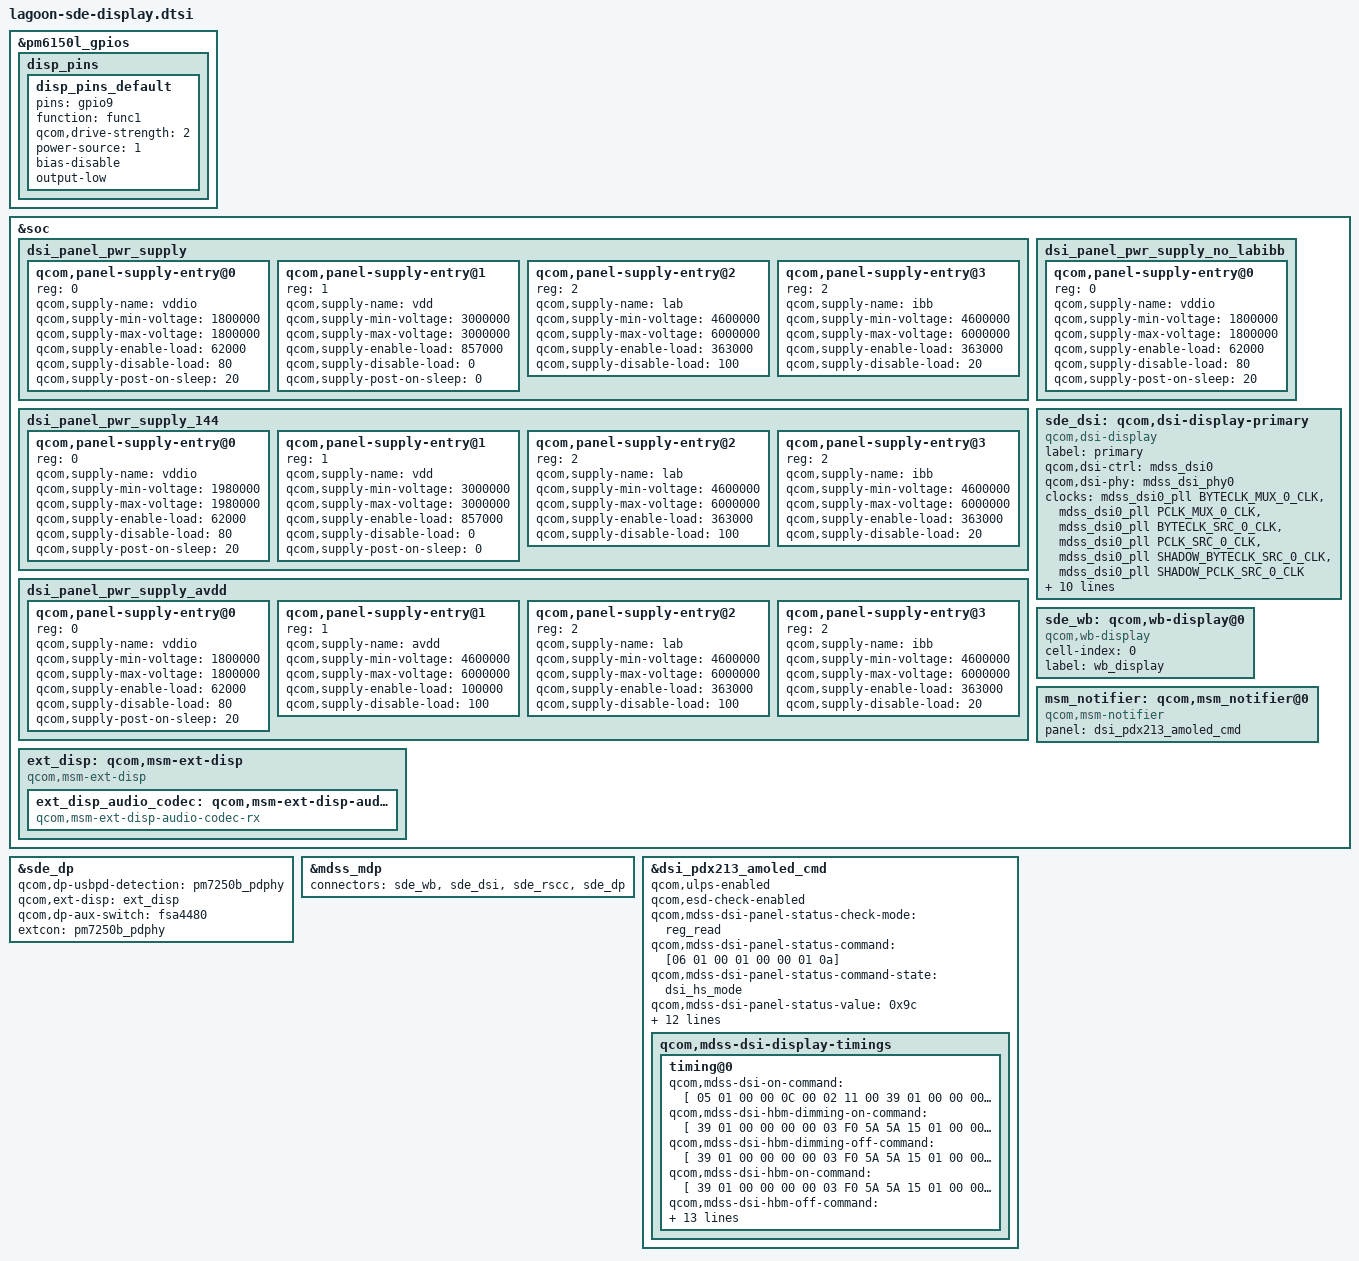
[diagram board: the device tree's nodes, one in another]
#include "dsi-panel-pdx213-amoled-fhd-cmd.dtsi"
#include <dt-bindings/clock/mdss-10nm-pll-clk.h>

&pm6150l_gpios {
	disp_pins {
		disp_pins_default: disp_pins_default {
			pins = "gpio9";
			function = "func1";
			qcom,drive-strength = <2>;
			power-source = <1>;
			bias-disable;
			output-low;
		};
	};
};

&soc {
	dsi_panel_pwr_supply: dsi_panel_pwr_supply {
		#address-cells = <1>;
		#size-cells = <0>;

		qcom,panel-supply-entry@0 {
			reg = <0>;
			qcom,supply-name = "vddio";
			qcom,supply-min-voltage = <1800000>;
			qcom,supply-max-voltage = <1800000>;
			qcom,supply-enable-load = <62000>;
			qcom,supply-disable-load = <80>;
			qcom,supply-post-on-sleep = <20>;
		};

		qcom,panel-supply-entry@1 {
			reg = <1>;
			qcom,supply-name = "vdd";
			qcom,supply-min-voltage = <3000000>;
			qcom,supply-max-voltage = <3000000>;
			qcom,supply-enable-load = <857000>;
			qcom,supply-disable-load = <0>;
			qcom,supply-post-on-sleep = <0>;
		};

		qcom,panel-supply-entry@2 {
			reg = <2>;
			qcom,supply-name = "lab";
			qcom,supply-min-voltage = <4600000>;
			qcom,supply-max-voltage = <6000000>;
			qcom,supply-enable-load = <363000>;
			qcom,supply-disable-load = <100>;
		};

		qcom,panel-supply-entry@3 {
			reg = <2>;
			qcom,supply-name = "ibb";
			qcom,supply-min-voltage = <4600000>;
			qcom,supply-max-voltage = <6000000>;
			qcom,supply-enable-load = <363000>;
			qcom,supply-disable-load = <20>;
		};
	};

	dsi_panel_pwr_supply_144: dsi_panel_pwr_supply_144 {
		#address-cells = <1>;
		#size-cells = <0>;

		qcom,panel-supply-entry@0 {
			reg = <0>;
			qcom,supply-name = "vddio";
			qcom,supply-min-voltage = <1980000>;
			qcom,supply-max-voltage = <1980000>;
			qcom,supply-enable-load = <62000>;
			qcom,supply-disable-load = <80>;
			qcom,supply-post-on-sleep = <20>;
		};

		qcom,panel-supply-entry@1 {
			reg = <1>;
			qcom,supply-name = "vdd";
			qcom,supply-min-voltage = <3000000>;
			qcom,supply-max-voltage = <3000000>;
			qcom,supply-enable-load = <857000>;
			qcom,supply-disable-load = <0>;
			qcom,supply-post-on-sleep = <0>;
		};

		qcom,panel-supply-entry@2 {
			reg = <2>;
			qcom,supply-name = "lab";
			qcom,supply-min-voltage = <4600000>;
			qcom,supply-max-voltage = <6000000>;
			qcom,supply-enable-load = <363000>;
			qcom,supply-disable-load = <100>;
		};

		qcom,panel-supply-entry@3 {
			reg = <2>;
			qcom,supply-name = "ibb";
			qcom,supply-min-voltage = <4600000>;
			qcom,supply-max-voltage = <6000000>;
			qcom,supply-enable-load = <363000>;
			qcom,supply-disable-load = <20>;
		};
	};

	dsi_panel_pwr_supply_avdd: dsi_panel_pwr_supply_avdd {
		#address-cells = <1>;
		#size-cells = <0>;

		qcom,panel-supply-entry@0 {
			reg = <0>;
			qcom,supply-name = "vddio";
			qcom,supply-min-voltage = <1800000>;
			qcom,supply-max-voltage = <1800000>;
			qcom,supply-enable-load = <62000>;
			qcom,supply-disable-load = <80>;
			qcom,supply-post-on-sleep = <20>;
		};

		qcom,panel-supply-entry@1 {
			reg = <1>;
			qcom,supply-name = "avdd";
			qcom,supply-min-voltage = <4600000>;
			qcom,supply-max-voltage = <6000000>;
			qcom,supply-enable-load = <100000>;
			qcom,supply-disable-load = <100>;
		};

		qcom,panel-supply-entry@2 {
			reg = <2>;
			qcom,supply-name = "lab";
			qcom,supply-min-voltage = <4600000>;
			qcom,supply-max-voltage = <6000000>;
			qcom,supply-enable-load = <363000>;
			qcom,supply-disable-load = <100>;
		};

		qcom,panel-supply-entry@3 {
			reg = <2>;
			qcom,supply-name = "ibb";
			qcom,supply-min-voltage = <4600000>;
			qcom,supply-max-voltage = <6000000>;
			qcom,supply-enable-load = <363000>;
			qcom,supply-disable-load = <20>;
		};
	};

	dsi_panel_pwr_supply_no_labibb: dsi_panel_pwr_supply_no_labibb {
		#address-cells = <1>;
		#size-cells = <0>;

		qcom,panel-supply-entry@0 {
			reg = <0>;
			qcom,supply-name = "vddio";
			qcom,supply-min-voltage = <1800000>;
			qcom,supply-max-voltage = <1800000>;
			qcom,supply-enable-load = <62000>;
			qcom,supply-disable-load = <80>;
			qcom,supply-post-on-sleep = <20>;
		};
	};

	sde_dsi: qcom,dsi-display-primary {
		compatible = "qcom,dsi-display";
		label = "primary";

		qcom,dsi-ctrl = <&mdss_dsi0>;
		qcom,dsi-phy = <&mdss_dsi_phy0>;

		clocks = <&mdss_dsi0_pll BYTECLK_MUX_0_CLK>,
			 <&mdss_dsi0_pll PCLK_MUX_0_CLK>,
			 <&mdss_dsi0_pll BYTECLK_SRC_0_CLK>,
			 <&mdss_dsi0_pll PCLK_SRC_0_CLK>,
			 <&mdss_dsi0_pll SHADOW_BYTECLK_SRC_0_CLK>,
			 <&mdss_dsi0_pll SHADOW_PCLK_SRC_0_CLK>;
		clock-names = "mux_byte_clk0", "mux_pixel_clk0",
				"src_byte_clk0", "src_pixel_clk0",
				"shadow_byte_clk0", "shadow_pixel_clk0";

		pinctrl-names = "panel_active", "panel_suspend";
		pinctrl-0 = <&sde_te_active &disp_pins_default>;
		pinctrl-1 = <&sde_te_suspend>;

		qcom,platform-te-gpio = <&tlmm 23 0>;
		qcom,panel-te-source = <0>;

		vddio-supply = <&L1E>;
		vdd-supply = <&L6A>;
		lab-supply = <&ab_vreg>;
		ibb-supply = <&ibb_vreg>;

		qcom,mdp = <&mdss_mdp>;
		qcom,dsi-default-panel = <&dsi_pdx213_amoled_cmd>;
	};

	sde_wb: qcom,wb-display@0 {
		compatible = "qcom,wb-display";
		cell-index = <0>;
		label = "wb_display";
	};

	msm_notifier: qcom,msm_notifier@0 {
		compatible = "qcom,msm-notifier";
		panel = <&dsi_pdx213_amoled_cmd>;
	};

	ext_disp: qcom,msm-ext-disp {
		compatible = "qcom,msm-ext-disp";

		ext_disp_audio_codec: qcom,msm-ext-disp-audio-codec-rx {
			compatible = "qcom,msm-ext-disp-audio-codec-rx";
		};
	};

};

&sde_dp {
	qcom,dp-usbpd-detection = <&pm7250b_pdphy>;
	qcom,ext-disp = <&ext_disp>;
	qcom,dp-aux-switch = <&fsa4480>;

	extcon = <&pm7250b_pdphy>;
};

&mdss_mdp {
	connectors = <&sde_wb &sde_dsi &sde_rscc &sde_dp>;
};

&dsi_pdx213_amoled_cmd {
	qcom,ulps-enabled;
	qcom,esd-check-enabled;
	qcom,mdss-dsi-panel-status-check-mode = "reg_read";
	qcom,mdss-dsi-panel-status-command = [06 01 00 01 00 00 01 0a];
	qcom,mdss-dsi-panel-status-command-state = "dsi_hs_mode";
	qcom,mdss-dsi-panel-status-value = <0x9c>;
	qcom,mdss-dsi-panel-on-check-value = <0x9c>;
	qcom,mdss-dsi-panel-status-read-length = <1>;

	qcom,mdss-dsi-panel-status-command1 = [06 01 00 01 00 00 01 0a];
	qcom,mdss-dsi-panel-status-command-state1 = "dsi_lp_mode";
	qcom,mdss-dsi-panel-status-value1 = <0x9c>;
	qcom,mdss-dsi-panel-status-read-length1 = <1>;

	qcom,dsi-select-clocks = "mux_byte_clk0", "mux_pixel_clk0";
	qcom,mdss-dsi-t-clk-post = <0x0A>;
	qcom,mdss-dsi-t-clk-pre = <0x1D>;
	qcom,mdss-dsi-display-timings {
		timing@0 {
				qcom,mdss-dsi-on-command = [
					05 01 00 00 0C 00 02 11 00

					39 01 00 00 00 00 03 F0 5A 5A
					15 01 00 00 00 00 02 35 00
					39 01 00 00 00 00 03 F0 A5 A5

					39 01 00 00 00 00 03 F0 5A 5A
					15 01 00 00 00 00 02 DF 03
					15 01 00 00 00 00 02 E0 01
					39 01 00 00 00 00 03 F0 A5 A5

					39 01 00 00 00 00 03 F0 5A 5A
					39 01 00 00 00 00 05 2A 00 00 04 37
					39 01 00 00 00 00 05 2B 00 00 09 D7
					39 01 00 00 00 00 03 F0 A5 A5

					39 01 00 00 00 00 03 F0 5A 5A
					15 01 00 00 00 00 02 53 28
					39 01 00 00 00 00 03 51 00 00
					39 01 00 00 00 00 02 55 00
					39 01 00 00 00 00 03 F0 A5 A5

					39 01 00 00 00 00 03 F0 5A 5A
					39 01 00 00 00 00 03 BE 92 09
					39 01 00 00 00 00 03 F0 A5 A5
					39 01 00 00 00 00 03 F0 5A 5A
					39 01 00 00 00 00 02 B0 06
					39 01 00 00 00 00 02 B6 90
					39 01 00 00 00 00 02 B0 0A
					39 01 00 00 00 00 05 B6 18 00 00 18
					39 01 00 00 00 00 03 F0 A5 A5

					05 01 00 00 00 00 02 29 00];
				qcom,mdss-dsi-hbm-dimming-on-command = [
						39 01 00 00 00 00 03 F0 5A 5A
						15 01 00 00 0A 00 02 53 E8
						05 01 00 00 96 00 03 51 03 FF
						39 01 00 00 00 00 03 F0 A5 A5
				];
				qcom,mdss-dsi-hbm-dimming-off-command = [
						39 01 00 00 00 00 03 F0 5A 5A
						15 01 00 00 0A 00 02 53 28
						05 01 00 00 96 00 03 51 00 00
						39 01 00 00 00 00 03 F0 A5 A5
				];
				qcom,mdss-dsi-hbm-on-command = [
						39 01 00 00 00 00 03 F0 5A 5A
						15 01 00 00 0A 00 02 53 E0
						05 01 00 00 96 00 03 51 03 FF
						39 01 00 00 00 00 03 F0 A5 A5
				];
				qcom,mdss-dsi-hbm-off-command = [
						39 01 00 00 00 00 03 F0 5A 5A
						15 01 00 00 0A 00 02 53 20
						05 01 00 00 96 00 03 51 00 00
						39 01 00 00 00 00 03 F0 A5 A5
				];
				qcom,mdss-dsi-hbm-dimming-on-command-state = "dsi_lp_mode";
				qcom,mdss-dsi-hbm-dimming-off-command-state = "dsi_lp_mode";
				qcom,mdss-dsi-hbm-on-command-state = "dsi_lp_mode";
				qcom,mdss-dsi-hbm-off-command-state = "dsi_lp_mode";

			qcom,mdss-dsi-panel-phy-timings = [00 16 08 08 14 16 08
							08 06 02 04 00];
			qcom,display-topology = <1 0 1>;
			qcom,default-topology-index = <0>;
		};
	};
};

